CM_ "IMPORT _toyota_2017.dbc"
CM_ "IMPORT _comma.dbc"

BO_ 359 STEERING_IPAS_COMMA: 8 IPAS
 SG_ STATE : 7|4@0+ (1,0) [0|15] "" XX

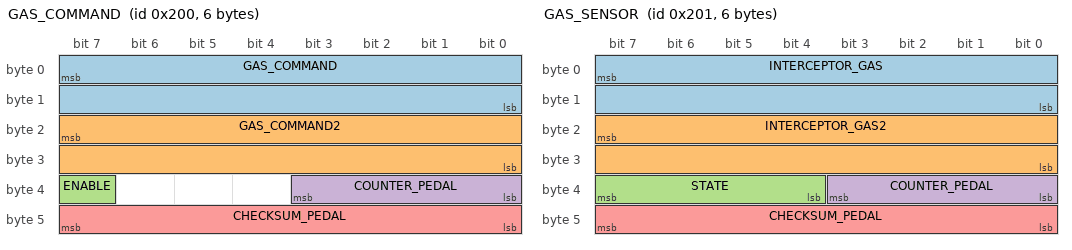
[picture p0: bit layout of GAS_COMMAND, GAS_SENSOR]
BO_ 512 GAS_COMMAND: 6 EON
 SG_ GAS_COMMAND : 7|16@0+ (0.159375,-75.555) [0|1] "" INTERCEPTOR
 SG_ GAS_COMMAND2 : 23|16@0+ (0.159375,-151.111) [0|1] "" INTERCEPTOR
 SG_ ENABLE : 39|1@0+ (1,0) [0|1] "" INTERCEPTOR
 SG_ COUNTER_PEDAL : 35|4@0+ (1,0) [0|15] "" INTERCEPTOR
 SG_ CHECKSUM_PEDAL : 47|8@0+ (1,0) [0|255] "" INTERCEPTOR

BO_ 513 GAS_SENSOR: 6 INTERCEPTOR
 SG_ INTERCEPTOR_GAS : 7|16@0+ (0.159375,-75.555) [0|1] "" EON
 SG_ INTERCEPTOR_GAS2 : 23|16@0+ (0.159375,-151.111) [0|1] "" EON
 SG_ STATE : 39|4@0+ (1,0) [0|15] "" EON
 SG_ COUNTER_PEDAL : 35|4@0+ (1,0) [0|15] "" EON
 SG_ CHECKSUM_PEDAL : 47|8@0+ (1,0) [0|255] "" EON

BO_ 550 BRAKE_MODULE: 8 XXX
 SG_ BRAKE_PRESSURE : 0|9@0+ (1,0) [0|511] "" XX

BO_ 581 GAS_PEDAL: 5 XXX
 SG_ GAS_PEDAL : 23|8@0+ (0.005,0) [0|1] "" XXX

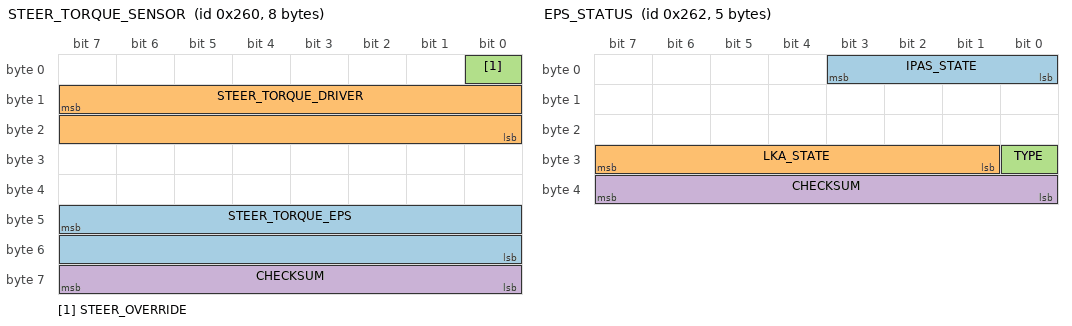
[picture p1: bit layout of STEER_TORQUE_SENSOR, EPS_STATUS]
BO_ 608 STEER_TORQUE_SENSOR: 8 XXX
 SG_ STEER_TORQUE_EPS : 47|16@0- (0.73,0) [-20000|20000] "" XXX
 SG_ STEER_TORQUE_DRIVER : 15|16@0- (1,0) [-32768|32767] "" XXX
 SG_ STEER_OVERRIDE : 0|1@0+ (1,0) [0|1] "" XXX
 SG_ CHECKSUM : 63|8@0+ (1,0) [0|255] "" XXX

BO_ 610 EPS_STATUS: 5 EPS
 SG_ IPAS_STATE : 3|4@0+ (1,0) [0|15] "" XXX
 SG_ LKA_STATE : 31|7@0+ (1,0) [0|127] "" XXX
 SG_ TYPE : 24|1@0+ (1,0) [0|1] "" XXX
 SG_ CHECKSUM : 39|8@0+ (1,0) [0|255] "" XXX

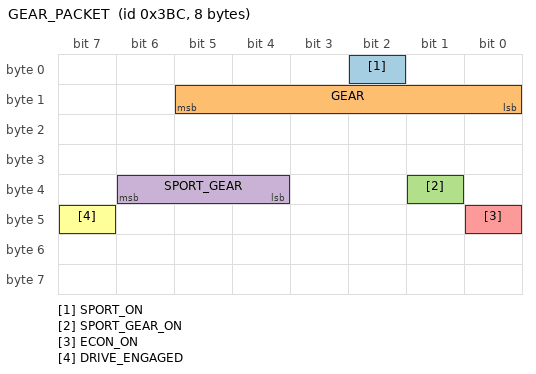
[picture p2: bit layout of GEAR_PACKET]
BO_ 956 GEAR_PACKET: 8 XXX
 SG_ SPORT_ON : 2|1@0+ (1,0) [0|1] "" XXX
 SG_ GEAR : 13|6@0+ (1,0) [0|63] "" XXX
 SG_ SPORT_GEAR_ON : 33|1@0+ (1,0) [0|1] "" XXX
 SG_ SPORT_GEAR : 38|3@0+ (1,0) [0|7] "" XXX
 SG_ ECON_ON : 40|1@0+ (1,0) [0|1] "" XXX
 SG_ DRIVE_ENGAGED : 47|1@0+ (1,0) [0|1] "" XXX

CM_ SG_ 581 GAS_PEDAL "it seems slightly filtered";
CM_ SG_ 610 TYPE "seems 1 on Corolla, 0 on all others";
VAL_ 513 STATE 5 "FAULT_TIMEOUT" 4 "FAULT_STARTUP" 3 "FAULT_SCE" 2 "FAULT_SEND" 1 "FAULT_BAD_CHECKSUM" 0 "NO_FAULT";
VAL_ 610 IPAS_STATE 5 "override" 3 "enabled" 1 "disabled";
VAL_ 610 LKA_STATE 25 "temporary_fault" 9 "temporary_fault2" 5 "active" 1 "standby";
VAL_ 956 SPORT_ON 0 "off" 1 "on";
VAL_ 956 GEAR 0 "D" 1 "S" 8 "N" 16 "R" 32 "P";
VAL_ 956 SPORT_GEAR_ON 0 "off" 1 "on";
VAL_ 956 SPORT_GEAR 1 "S1" 2 "S2" 3 "S3" 4 "S4" 5 "S5" 6 "S6";
VAL_ 956 ECON_ON 0 "off" 1 "on";
VAL_ 956 DRIVE_ENGAGED 0 "off" 1 "on";
BO_ 359 STEERING_IPAS_COMMA: 8 IPAS
SG_ STATE : 7|4@0+ (1,0) [0|15] "" X";
BO_ 550 BRAKE_MODULE: 8 XXX
SG_ BRAKE_PRESSURE : 0|9@0+ (1,0) [0|511] "" X";
